# AM13E23219 register map
Vendor: Texas Instruments; File version: 1.0
CPU: CM33 r0p1, little endian, MPU, FPU, VTOR, 4 interrupt priority bits
Registers are 32-bit, read-write, reset 0x0 unless marked. A register's access mark holds for its fields unless they carry their own. Offsets are from the block's base; [hi:lo] are bit positions; lines under a group give offsets from that group; {n}, {i} and the like mark numbered series; 'fields as' and 'values as' point back to an identical list; <NAME> marks a mode.

## UC0_I2CT — UNICOMMI2CT module
Base 0x40610000
Same registers: UC1_I2CT 0x40611000, UC2_I2CT 0x40612000, UC3_I2CT 0x40650000, UC4_I2CT 0x40651000, UC5_I2CT 0x40652000
0x00 CLKDIV — Clock Divider
  [2:0] RATIO — Selects divide ratio of module clock Division factor 0 : DIV_BY_1 1 : DIV_BY_2 .... 63: DIV_BY_64
    0=DIV_BY_1 (Do not divide clock source); {v}=DIV_BY_{v+1} (Divide clock source by {v+1}) (v=1..7); {v}=DIV_BY_{v+1} (Divide clock source by 8) (v=60..63)
0x08 CLKSEL — Clock Select for Ultra Low Power peripherals
  [3] BUSCLK_SEL — Selects BUS CLK as clock source if enabled
    0=DISABLE (Does not select this clock as a source); 1=ENABLE (Select this clock as a source)
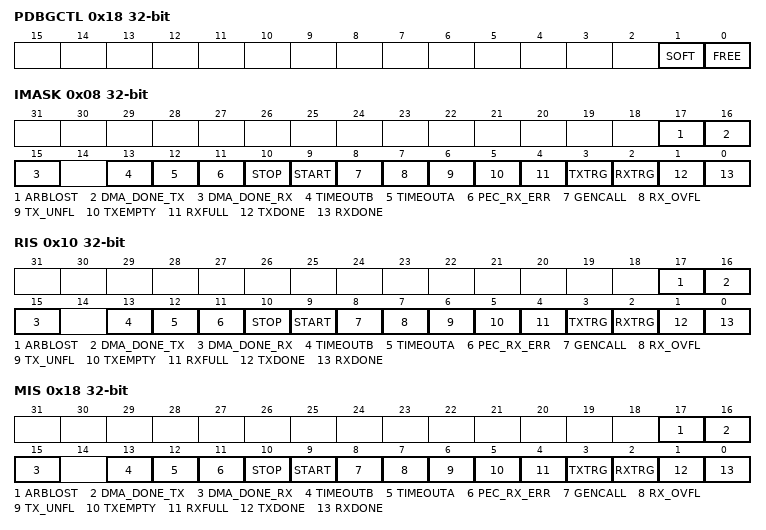
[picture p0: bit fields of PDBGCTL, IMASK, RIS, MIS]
0x18 PDBGCTL — Peripheral Debug Control
  [1] SOFT — Soft halt boundary control. This function is only available, if [FREE] is set to 'STOP'
    0=DEPRECATED (Not supported); 1=DELAYED (The peripheral blocks the debug freeze until it has reached a boundary where it can resume without corruption)
  [0] FREE — Free run control
    0=STOP (The peripheral freezes functionality while the Core Halted input is asserted and resumes when it is deasserted.); 1=RUN (The peripheral ignores the state of the Core Halted input)
0x20 CPU_INT group
  0x00 IIDX ro — Interrupt index
    [7:0] STAT — I2C Module Interrupt Vector Value. This register provides the highes priority interrupt index. A read clears the corresponding interrupt flag in RIS and MISC. 15h-1Fh = Reserved
      0=NO_INTR (No interrupt pending); 1=RXDONEFG (Receive Done Flag); 2=TXDONEFG (Transmit Done Flag); 3=RXTRG (receive FIFO Trigger Level); 4=TXTRG (transmit FIFO Trigger level); 5=RXFULL (RX FIFO FULL Event/interrupt pending); 6=TXEMPTY (Transmit FIFO/Buffer Empty Event/interrupt pending); 7=TX_UNFL (Target TX FIFO underflow); 8=RX_OVFL (Target RX FIFO overflow event); 9=GENCALL (General Call Event); 10=STARTFG (Start Event); 11=STOPFG (Stop Event); 12=PEC_RX_ERR (PEC receive error event); 13=TIMEOUTA (Timeout A Event); 14=TIMEOUTB (Timeout B Event); 16=DMA_DONE_RX (DMA DONE on Channel RX); 17=DMA_DONE_TX (DMA DONE on Channel TX); 18=ARBLOSTFG (Arbitration Lost); 19=DMA_PREIRQ_RX (DMA PRE IRQ INTERRUPT); 20=DMA_PREIRQ_TX (DMA PRE IRQ INTERRUPT)
  0x08 IMASK — Interrupt mask
    [all] fields
      0=CLR (Clear Interrupt Mask); 1=SET (Set Interrupt Mask)
    [17] ARBLOST — Arbitration Lost Interrupt
    [16] DMA_DONE_TX — DMA done for channel 2
    [15] DMA_DONE_RX — DMA done for channel 3
    [13] TIMEOUTB — Timeout B Interrupt
    [12] TIMEOUTA — Timeout A Interrupt
    [11] PEC_RX_ERR — RX Pec Error Interrupt
    [10] STOP
    [9] START
    [8] GENCALL — General Call Interrupt
    [7] RX_OVFL — Target RX FIFO overflow
    [6] TX_UNFL — Target TX FIFO underflow
    [5] TXEMPTY — Target Transmit FIFO Empty interrupt mask
    [4] RXFULL — RXFIFO full event
    [3] TXTRG — Transmit FIFO Trigger
    [2] RXTRG — Receive FIFO Trigger
    [1] TXDONE — Transmit Transaction completed Interrupt
    [0] RXDONE — Receive Data Interrupt Signals that a byte has been received
  0x10 RIS — Raw interrupt status
    [17] ARBLOST — Arbitration Lost Interrupt
      0=CLR (Interrupt did not occur); 1=SET (Set Interrupt Mask)
    [16] DMA_DONE_TX — DMA Done on Event Channel TX
      0=CLR (Clear interrupt); 1=SET (Set interrupt)
    [15] DMA_DONE_RX — DMA Done on Event Channel RX
      0=CLR (Clear interrupt); 1=SET (Set interrupt)
    [13] TIMEOUTB — Timeout B Interrupt
      0=CLR (Interrupt did not occur); 1=SET (Interrupt occured)
    [12] TIMEOUTA — Timeout A Interrupt
      0=CLR (Interrupt did not occur); 1=SET (Set Interrupt Mask)
    [11] PEC_RX_ERR — RX Pec Error Interrupt
      0=CLR (Interrupt did not occur); 1=SET (Interrupt ocuured)
    [10] STOP — Stop Condition Interrupt: set on a STOP condition if this target was being addressed
      0=CLR (Clear Interrupt); 1=SET (Interrupt is set when target is addressed and STOP condition is received)
    [9] START — Start Condition Interrupt: is set after a START condition is received and this target is addressed
      0=CLR (Clear interrupt); 1=SET (Set when a START condition is receivied and address matches target's address)
    [8] GENCALL — General Call Interrupt: set when a general call is received
      0=CLR (Clear Interrupt Mask); 1=SET (Set Interrupt Mask)
    [7] RX_OVFL — Receive FIFO overflow
      0=CLR (Interrupt did not occur); 1=SET (Interrupt Occured)
    [6] TX_UNFL — Transmit FIFO underflow
      0=CLR (Interrupt did not occur); 1=SET (Interrupt occured)
    [5] TXEMPTY — Transmit FIFO Empty interrupt mask
      0=CLR (Interrupt did not occur); 1=SET (Interrupt occured)
    [4] RXFULL — RXFIFO full event
      0=CLR (Clear Interrupt Mask); 1=SET (Interrupt occured)
    [3] TXTRG — Transmit FIFO Trigger
      0=CLR (Clear Interrupt Mask); 1=SET (Set Interrupt Mask)
    [2] RXTRG — Receive FIFO Trigger
      0=CLR (Clear Interrupt Mask); 1=SET (Set Interrupt Mask)
    [1] TXDONE — Transmission Done Interrupt: Set after a byte is transmitted
      0=CLR (Interrupt did not occur); 1=SET (Set Interrupt Mask)
    [0] RXDONE — Receive Done Interrupt: Set after a byte is received
      0=CLR (Interrupt did not occur); 1=SET (Set Interrupt Mask)
  0x18 MIS — Masked interrupt status
    [17] ARBLOST — Arbitration Lost Interrupt
      0=CLR (Interrupt did not occur); 1=SET (Set Interrupt Mask)
    [16] DMA_DONE_TX — DMA Done on Event Channel TX
      0=CLR (Clear MIS); 1=SET (Set MIS)
    [15] DMA_DONE_RX — DMA Done on Event Channel RX
      0=CLR (Clear MIS); 1=SET (Set MIS)
    [13] TIMEOUTB — Timeout B Interrupt
      0=CLR (Clear interrupt mask); 1=SET (Set interrupt mask)
    [12] TIMEOUTA — Timeout A Interrupt
      0=CLR (Interrupt did not occur); 1=SET (Set Interrupt Mask)
    [11] PEC_RX_ERR — Target RX Pec Error Interrupt
      0=CLR (Clear interrupt mask); 1=SET (Set interrupt mask)
    [10] STOP — STOP Detection Interrupt
      0=CLR (Clear MIS); 1=SET (Set MIS)
    [9] START — START Detection Interrupt
      0=CLR (Clear MIS); 1=SET (Set MIS)
    [8] GENCALL — General Call Interrupt
      0=CLR (Interrupt did not occur); 1=SET (Set Interrupt Mask)
    [7] RX_OVFL — Target RX FIFO overflow
      0=CLR (Clear interrupt mask); 1=SET (Set interrupt mask)
    [6] TX_UNFL — Target TX FIFO underflow
      0=CLR (Clear interrupt mask); 1=SET (Set interrupt mask)
    [5] TXEMPTY — Transmit FIFO Empty interrupt mask
      0=CLR (Interrupt did not occur); 1=SET (Interrupt occured)
    [4] RXFULL — RXFIFO full event
      0=CLR (Clear Interrupt Mask); 1=SET (Interrupt occured)
    [3] TXTRG — Transmit FIFO Trigger
      0=CLR (Clear Interrupt Mask); 1=SET (Set Interrupt Mask)
    [2] RXTRG — Receive FIFO Trigger
      0=CLR (Clear Interrupt Mask); 1=SET (Set Interrupt Mask)
    [1] TXDONE — Transmit Transaction completed Interrupt
      0=CLR (Interrupt did not occur); 1=SET (Set Interrupt Mask)
    [0] RXDONE — Receive Data Interrupt Signals that a byte has been received
      0=CLR (Interrupt did not occur); 1=SET (Set Interrupt Mask)
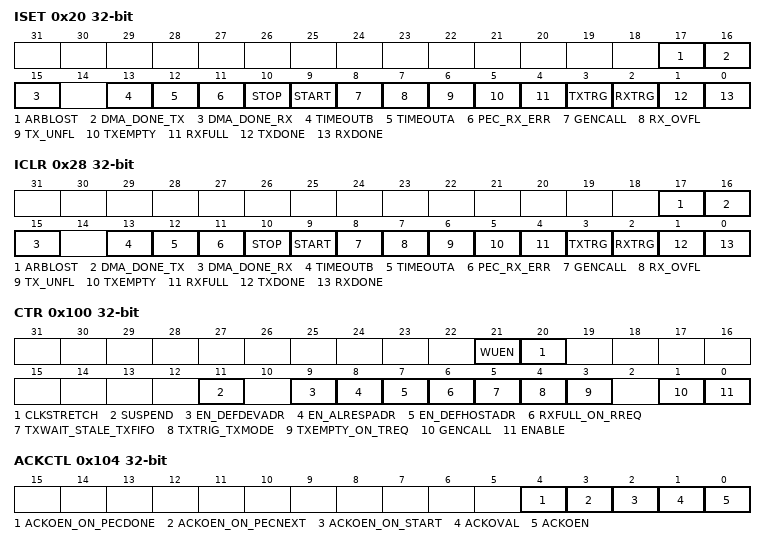
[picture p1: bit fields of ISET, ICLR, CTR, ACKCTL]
  0x20 ISET — Interrupt set
    [17] ARBLOST — Arbitration Lost Interrupt
      0=NO_EFFECT (Writing 0 has no effect); 1=SET (Set Interrupt Mask)
    [16] DMA_DONE_TX — DMA Done on Event Channel TX
      0=NO_EFFECT (Writing 0 has no effect); 1=SET (Set interrupt)
    [15] DMA_DONE_RX — DMA Done on Event Channel RX
      0=NO_EFFECT (Writing 0 has no effect); 1=SET (Set interrupt)
    [13] TIMEOUTB — Timeout B Interrupt
      0=NO_EFFECT (Writing 0 has no effect); 1=SET (Set interrupt)
    [12] TIMEOUTA — Timeout A interrupt
      values as ARBLOST
    [11] PEC_RX_ERR — Target RX Pec Error Interrupt
      0=NO_EFFECT (Writing 0 has no effect); 1=SET (Set interrupt)
    [10] STOP — Stop Condition Interrupt
      0=NO_EFFECT (Writing 0 has no effect); 1=SET (Set interrupt)
    [9] START — Start Condition Interrupt
      0=NO_EFFECT (Writing 0 has no effect); 1=SET (Set interrupt)
    [8] GENCALL — General Call Interrupt
      values as ARBLOST
    [7] RX_OVFL — Target RX FIFO overflow
      0=NO_EFFECT (Writing 0 has no effect); 1=SET (Set interrupt)
    [6] TX_UNFL — Target TX FIFO underflow
      0=NO_EFFECT (Writing 0 has no effect); 1=SET (Set interrupt)
    [5] TXEMPTY — Transmit FIFO Empty interrupt mask
      0=NO_EFFECT (Writing 0 has no effect); 1=SET (Set Interrupt)
    [4] RXFULL — RXFIFO full event
      0=NO_EFFECT (Clear Interrupt Mask); 1=SET (Set Interrupt)
    [3] TXTRG — Target Transmit FIFO Trigger
      0=NO_EFFECT (Clear Interrupt Mask); 1=SET (Set Interrupt Mask)
    [2] RXTRG — Target Receive FIFO Trigger
      values as TXTRG
    [1] TXDONE — Target Transmit Transaction completed Interrupt
      values as ARBLOST
    [0] RXDONE — Target Receive Data Interrupt Signals that a byte has been received
      values as ARBLOST
  0x28 ICLR — Interrupt clear
    [17] ARBLOST — Arbitration Lost Interrupt
      0=NO_EFFECT (Writing 0 has no effect); 1=CLR (Set Interrupt Mask)
    [16] DMA_DONE_TX — DMA Done on Event Channel TX
      0=NO_EFFECT (Writing 0 has no effect); 1=CLR (Clear interrupt)
    [15] DMA_DONE_RX — DMA Done on Event Channel RX
      values as DMA_DONE_TX
    [13] TIMEOUTB — Timeout B Interrupt
      0=NO_EFFECT (Writing 0 has no effect); 1=CLR (Clear Interrupt)
    [12] TIMEOUTA — Timeout A interrupt
      values as ARBLOST
    [11] PEC_RX_ERR — Target RX Pec Error Interrupt
      values as TIMEOUTB
    [10] STOP — Target STOP Detection Interrupt
      values as DMA_DONE_TX
    [9] START — Target START Detection Interrupt
      values as DMA_DONE_TX
    [8] GENCALL — General Call Interrupt
      values as ARBLOST
    [7] RX_OVFL — Target RX FIFO overflow
      values as TIMEOUTB
    [6] TX_UNFL — Target TX FIFO underflow
      values as TIMEOUTB
    [5] TXEMPTY — Transmit FIFO Empty interrupt mask
      values as TIMEOUTB
    [4] RXFULL — RXFIFO full event
      0=NO_EFFECT (Clear Interrupt Mask); 1=CLR (Clear Interrupt)
    [3] TXTRG — Target Transmit FIFO Trigger
      0=NO_EFFECT (Clear Interrupt Mask); 1=CLR (Set Interrupt Mask)
    [2] RXTRG — Target Receive FIFO Trigger
      values as TXTRG
    [1] TXDONE — Target Transmit Transaction completed Interrupt
      values as ARBLOST
    [0] RXDONE — Target Receive Data Interrupt Signals that a byte has been received
      values as ARBLOST
0x50 DMA_TRIG1 group
  0x08 IMASK — Interrupt mask
    [2] RXTRG — Target Receive FIFO Trigger
      0=CLR (Clear Interrupt Mask); 1=SET (Set Interrupt Mask)
  0x10 RIS — Raw interrupt status
    fields as DMA_TRIG1.IMASK
  0x18 MIS — Masked interrupt status
    fields as DMA_TRIG1.IMASK
  0x20 ISET — Interrupt set
    [2] RXTRG — Target Receive FIFO Trigger
      values as CPU_INT.ISET.TXTRG
0x80 DMA_TRIG0 group
  0x08 IMASK — Interrupt mask
    [3] TXTRG — Target Transmit FIFO Trigger
      0=CLR (Clear Interrupt Mask); 1=SET (Set Interrupt Mask)
  0x10 RIS — Raw interrupt status
    fields as DMA_TRIG0.IMASK
  0x18 MIS — Masked interrupt status
    fields as DMA_TRIG0.IMASK
  0x20 ISET — Interrupt set
    [3] TXTRG — Target Transmit FIFO Trigger
      values as CPU_INT.ISET.TXTRG
0xE4 INTCTL — Interrupt control register
  [0] INTEVAL — Writing a 1 to this field re-evaluates the interrupt sources.
    0=DISABLE (The interrupt or event line is disabled.); 1=EVAL (The interrupt or event line is in software mode. Software must clear the RIS.)
0x100 CTR — I2C Target Control Register
  [21] WUEN — Target Wakeup Enable
    0=DISABLE (When 0, the Target is not allowed to clock stretch on START detection); 1=ENABLE (When 1, the Target is allowed to clock stretch on START detection and wait for faster clock to be abvailable. This allows clean wake up support for I2C in low power mode use cases)
  [20] CLKSTRETCH — Clock Stretch Enable
    0=DISABLE (clock stretching is disabled); 1=ENABLE (clock stretching is enabled)
  [11] SUSPEND — Suspend external communication
    0=DISABLE (Functional mode resumed); 1=ENABLE (External communication suspended)
  [9] EN_DEFDEVADR — Enable Default device address
    0=DISABLE (When this bit is 0, the default device address is not matched. NOTE: it may still be matched if programmed inside SOAR/SOAR2.); 1=ENABLE (When this bit is 1, default device address of 7h110_0001 is always matched by the Target address match logic.)
  [8] EN_ALRESPADR — Enable Alert Response Address
    0=DISABLE (When this bit is 0, the alert response address is not matched. NOTE: it may still be matched if programmed inside SOAR/SOAR2); 1=ENABLE (When this bit is 1, alert response address of 7h000_1100 is always matched by the Target address match logic.)
  [7] EN_DEFHOSTADR — Enable Default Host Address
    0=DISABLE (When this bit is 0, the default host address is not matched NOTE: it may still be matched if programmed inside SOAR/SOAR2); 1=ENABLE (When this bit is 1, default host address of 7h000_1000 is always matched by the Target address match logic.)
  [6] RXFULL_ON_RREQ — Rx full interrupt generated on RREQ condition as indicated in SSR
    0=DISABLE (When 0, RIS:SRXFULL will be set when only the Target RX FIFO is full. This allows the SRXFULL interrupt to be used to indicate that the I2C bus is being clock stretched and that the FW must either read the RX FIFO or ACK/NACK the current Rx byte.); 1=ENABLE (When 1, RIS:SRXFULL will be set when the Target State Machine is in the RX_WAIT or RX_ACK_WAIT states which occurs when the I2C transaction is clock stretched because the RX FIFO is full or the ACKOEN has been set and the state machine is waiting for FW to ACK/NACK the current byte.)
  [5] TXWAIT_STALE_TXFIFO — Tx transfer waits when stale data in Tx FIFO. This prevents stale bytes left in the TX FIFO from automatically being sent on the next I2C packet. Note: this should be used with TXEMPTY_ON_TREQ set to prevent the Target State Machine from waiting for TX FIFO data without an interrupt notification when the FIFO data is stale.
    0=DISABLE (When 0, the TX FIFO empty signal to the Target State Machine indicates that the TX FIFO is empty.); 1=ENABLE (When 1, the TX FIFO empty signal to the Target State Machine will indicate that the TX FIFO is empty or that the TX FIFO data is stale. The TX FIFO data is determined to be stale when there is data in the TX FIFO when the Target State Machine leaves the TXMODE as defined in the SSR register. This can occur is a Stop or timeout occur when there are bytes left in the TX FIFO.)
  [4] TXTRIG_TXMODE — Tx Trigger when Target FSM is in Tx Mode
    0=DISABLE (No special behavior); 1=ENABLE (When 1, RIS:TXTRG will be set when the Target TX FIFO has reached the trigger level AND the Target State Machine is in the TXMODE as defined in the SSR register. When cleared RIS:TXTRG will be set when the Target TX FIFO is at or above the trigger level. This setting can be used to hold off the TX DMA until a transaction starts. This allows the DMA to be configured when the I2C is idle but have it wait till the transaction starts to load the Target TX FIFO, so it can load from a memory buffer that might be changing over time.)
  [3] TXEMPTY_ON_TREQ — Tx Empty Interrupt on TREQ
    0=DISABLE (When 0, RIS:TXEMPTY will be set when only the Target TX FIFO is empty. This allows the TXEMPTY interrupt to be used to indicate that the I2C bus is being clock stretched and that Target TX data is required.); 1=ENABLE (When 1, RIS:TXEMPTY will be set when the Target State Machine is in the TX_WAIT state which occurs when the TX FIFO is empty AND the I2C transaction is clock stretched waiting for the FIFO to receive data.)
  [1] GENCALL — General call response enable Modify only when UCSWRST = 1. 0b = Do not respond to a general call 1b = Respond to a general call
    0=DISABLE (Do not respond to a general call); 1=ENABLE (Respond to a general call)
  [0] ENABLE — Setting this bit enables the module.
    0=DISABLE (Disables module operation.); 1=ENABLE (Enables module operation.)
0x104 ACKCTL — I2C Target ACK Control
  [4] ACKOEN_ON_PECDONE — When set, this bit will automatically turn on target acknowledge enable field following the ACK/NACK of the received PEC byte. Status bit ACKOEN will reflect a value of '1' when automatic override enable is used.
    0=DISABLE (No special behavior); 1=ENABLE (When set this bit will automatically turn on the Target ACKOEN field following the ACK/NACK of the received PEC byte.)
  [3] ACKOEN_ON_PECNEXT — When set this bit will automatically turn on the Target acknowledge override following a ACK/NACK of the byte received just prior to the PEC byte. However, setting ACKCTL.ACKOEN bit will not automatically be ACKed/NACKed by the State Machine and firmware must perform this function by writing Target.ACKCTL register. Status bit ACKOEN will reflect a value of '1' when automatic override enable is used.
    0=DISABLE (No special behavior); 1=ENABLE (When set this bit will automatically turn on the Target ACKOEN field following the ACK/NACK of the byte received just prior to the PEC byte. Note that when ACKOEN is set the PEC byte will not automatically be ACKed/NACKed by the State Machine and FW must perform this function by writing Target_SACKCTL.)
  [2] ACKOEN_ON_START — When set this bit will automatically enable target override acknowlede following a Start Condition. Status bit ACKOEN will reflect a value of '1' when automatic override enable is used.
    0=DISABLE (No special behavior); 1=ENABLE (When set this bit will automatically turn on the Target ACKOEN field following a Start Condition.)
  [1] ACKOVAL — ACK Override Value Note: Override control is not applicable to Address frame. Bytes following address frame can be acknowledged using ACKOVAL.
    0=DISABLE (An ACK is sent indicating valid data or command.); 1=ENABLE (A NACK is sent indicating invalid data or command.)
  [0] ACKOEN — I2C Target ACK Override Enable Read SR.ACKOEN to check current status of this bit
    0=DISABLE (A response in not provided.); 1=ENABLE (An ACK or NACK is sent according to the value written to the ACKOVAL bit.)
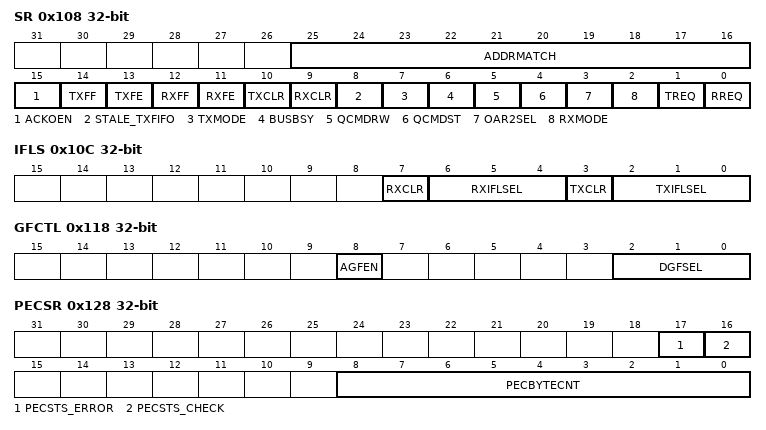
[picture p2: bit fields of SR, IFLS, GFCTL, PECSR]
0x108 SR access per field — Status Register
  [25:16] ADDRMATCH rw — Indicates the address for which Target address match happened
    0=MINIMUM (Minimum Value); 0x3FF=MAXIMUM (Maximum Value)
  [15] ACKOEN ro — Status of ACK Override Enable
    0=DISABLE (ACK override is disabled); 1=ENABLE (ACK override was enabled in design)
  [14] TXFF ro — Transmit FIFO Full The meaning of this bit depends on the state of the FEN bit in the CTL0 register.
    0=CLEARED (The transmitter is not full.); 1=SET (If the FIFO is disabled (FEN is 0), the transmit holding register is full. If the FIFO is enabled (FEN is 1), the transmit FIFO is full.)
  [13] TXFE ro — Transmit FIFO Empty The meaning of this bit depends on the state of the FEN bit in the CTL0 register.
    0=CLEARED (The transmitter has data to transmit.); 1=SET (If the FIFO is disabled (FEN is 0), the transmit holding register is empty. If the FIFO is enabled (FEN is 1), the transmit FIFO is empty.)
  [12] RXFF ro — Receive FIFO Full The meaning of this bit depends on the state of the FEN bit in the CTL0 register.
    0=CLEARED (The receiver can receive data.); 1=SET (If the FIFO is disabled (FEN is 0), the receive holding register is full. If the FIFO is enabled (FEN is 1), the receive FIFO is full.)
  [11] RXFE ro — Receive FIFO Empty The meaning of this bit depends on the state of the FEN bit in the CTL0 register.
    0=CLEARED (The receiver is not empty.); 1=SET (If the FIFO is disabled (FEN is 0), the receive holding register is empty. If the FIFO is enabled (FEN is 1), the receive FIFO is empty.)
  [10] TXCLR ro — TX FIFO Clear Status
    0=CLEARED (FIFO is not cleared); 1=SET (FIFO clear is complete)
  [9] RXCLR ro — RX FIFO Clear Status
    values as TXCLR
  [8] STALE_TXFIFO rw
    0=CLEARED (Tx FIFO is not stale); 1=SET (The TX FIFO is stale. This occurs when the TX FIFO was not emptied during the previous I2C transaction.)
  [7] TXMODE rw — FSM is in TX MODE
    0=CLEARED (State Machine is not in TX_DATA, TX_WAIT, TX_ACK or ADDR_ACK state with the bus direction set to read.); 1=SET (State Machine is in TX_DATA, TX_WAIT, TX_ACK or ADDR_ACK state with the bus direction set to read.)
  [6] BUSBSY rw — I2C bus is busy
    0=CLEARED (The I2C Bus is not busy); 1=SET (The I2C Bus is busy. This is cleared on a timeout.)
  [5] QCMDRW ro — Quick Command Read / Write This bit only has meaning when the QCMDST bit is set. Value Description: 0: Quick command was a write 1: Quick command was a read
    0=CLEARED (Quick command was a write); 1=SET (Quick command was a read)
  [4] QCMDST ro — Quick Command Status Value Description: 0: The last transaction was a normal transaction or a transaction has not occurred. 1: The last transaction was a Quick Command transaction
    0=CLEARED (The last transaction was a normal transaction or a transaction has not occurred.); 1=SET (The last transaction was a Quick Command transaction.)
  [3] OAR2SEL ro — OAR2 Address Matched This bit gets reevaluated after every address comparison.
    0=CLEARED (Either the OAR2 address is not matched or the match is in legacy mode.); 1=SET (OAR2 address matched and ACKed by the Target.)
  [2] RXMODE rw — Target FSM is in Rx MODE
    0=CLEARED (The Target State Machine is not in the RX_DATA, RX_ACK, RX_WAIT, RX_ACK_WAIT or ADDR_ACK state with the bus direction set to write.); 1=SET (The Target State Machine is in the RX_DATA, RX_ACK, RX_WAIT, RX_ACK_WAIT or ADDR_ACK state with the bus direction set to write.)
  [1] TREQ ro — Transmit Request
    0=CLEARED (No outstanding transmit request.); 1=SET (I2C Target is addressed as a transmitter and is using clock stretching to delay the Controller until data has been written to the TXDATA FIFO (TX FIFO is empty).)
  [0] RREQ ro — Receive Request
    0=CLEARED (No outstanding receive data.); 1=SET (Module has outstanding receive data and is using clock stretching to delay the Controller until the data has been read from the RXDATA FIFO (RX FIFO is full).)
0x10C IFLS — Interrupt FIFO Level Select Register
  [7] RXCLR — RX FIFO CLEAR
    0=DISABLE (Disable FIFO clear); 1=ENABLE (Enable FIFO Clear)
  [6:4] RXIFLSEL — FIFO Level Select for generating events (interrupt/dma). Note: for undefined settings the default configuration is used.
    1=LVL_1_4 (RX FIFO >= 1/4 full); 2=LVL_1_2 (RX FIFO >= 1/2 full (default)); 3=LVL_3_4 (RX FIFO >= 3/4 full); 4=LVL_NOT_EMPTY (Opposite of empty); 5=LVL_FULL (RX FIFO is full); 6=LVL_ALMOST_FULL (RX_FIFO >= (MAX_FIFO_LEN -1)); 7=LVL_ALMOST_EMPTY (RX_FIFO <= 1)
  [3] TXCLR — RX FIFO Flush
    0=DISABLE (Disable FIFO clear); 1=ENABLE (Enable FIFO Clear)
  [2:0] TXIFLSEL — FIFO Level Select for generating events (interrupt/dma). Note: for undefined settings the default configuration is used.
    1=LVL_3_4 (TX FIFO <= 3/4 empty); 2=LVL_1_2 (TX FIFO <= 1/2 empty (default)); 3=LVL_1_4 (TX FIFO <= 1/4 empty); 4=LVL_NOT_FULL (Opposite of full); 5=LVL_EMPTY (TX FIFO is empty); 6=LVL_ALMOST_EMPTY (TX FIFO <= 1); 7=LVL_ALMOST_FULL (TX_FIFO >= (MAX_FIFO_LEN -1))
0x118 GFCTL — I2C Glitch Filter Control
  [8] AGFEN — Analog Glitch Suppression Enable
    0=DISABLE (Analog Glitch Filter disable); 1=ENABLE (Analog Glitch Filter enable)
  [2:0] DGFSEL — Glitch Suppression Pulse Width This field controls the pulse width select for glitch suppression on the SCL and SDA lines. The following values are the glitch suppression values in terms of functional clocks. (Core Domain only)
    0=DISABLED (Bypass); 1=CLK_1 (1 clock); 2=CLK_2 (2 clocks); 3=CLK_3 (3 clocks); 4=CLK_4 (4 clocks); 5=CLK_8 (8 clocks); 6=CLK_16 (16 clocks); 7=CLK_31 (31 clocks)
0x120 TTXDATA — I2C TXData
  [7:0] DATA — Transmit Data This byte contains the data to be transferred during the next transaction.
    0=MINIMUM (Smallest value); 255=MAXIMUM (Highest possible value)
0x124 RXDATA ro — I2C RXData
  [7:0] DATA — Received Data. This field contains the last received data.
    values as TTXDATA.DATA
0x128 PECSR — PEC status register
  [17] PECSTS_ERROR — This status bit indicates if a PEC check error occurred in the transaction that occurred before the last Stop. Latched on Stop.
    0=CLEARED (Indicates PEC check error did not occurr in the transaction that occurred before the last Stop); 1=SET (Indicates PEC check error occurred in the transaction that occurred before the last Stop)
  [16] PECSTS_CHECK — This status bit indicates if the PEC was checked in the transaction that occurred before the last Stop. Latched on Stop.
    0=CLEARED (Indicates PEC was not checked in the transaction that occurred before the last Stop); 1=SET (Indicates PEC was checked in the transaction that occurred before the last Stop)
  [8:0] PECBYTECNT — This is the current PEC Byte Count of the State Machine.
    0=MINIMUM (Minimum Value); 0x1FF=MAXIMUM (Maximum Value)
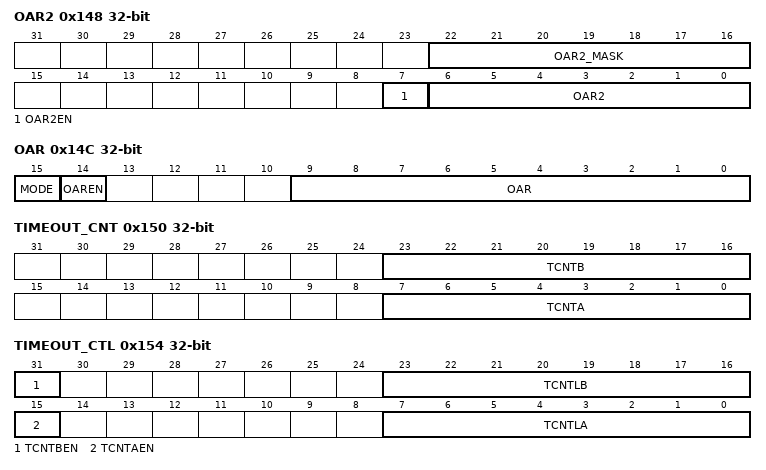
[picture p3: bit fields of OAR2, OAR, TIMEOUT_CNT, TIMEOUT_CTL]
0x148 OAR2 — Own Address 2
  [22:16] OAR2_MASK — Own Address 2 Mask: This field specifies bits A6 through A0 of the Target address. The bits with value 1 in SOAR2.OAR2_MASK field will make the corresponding incoming address bits to match by default regardless of the value inside SOAR2.OAR2 i.e. corresponding SOAR2.OAR2 bit is a dont care.
    0=MINIMUM (Minimum Value); 127=MAXIMUM (Maximum Value)
  [7] OAR2EN — Own Address 2 Enable
    0=DISABLE (The alternate address is disabled.); 1=ENABLE (Enables the use of the alternate address in the OAR2 field.)
  [6:0] OAR2 — Own Address 2This field specifies the alternate OAR2 address.
    0=MINIMUM (Smallest value); 127=MAXIMUM (Highest possible value)
0x14C OAR — I2C Own Address
  [15] MODE — This bit selects the adressing mode to be used. When 0, 7-bit addressing is used. When 1, 10-bit addressing is used.
    0=Enable 7-bit addressing; 1=Enable 10-bit addressing
  [14] OAREN — Own Address Enable
    0=DISABLE (Disable OAR address); 1=ENABLE (Enable OAR address)
  [9:0] OAR — Own Address: This field specifies bits A9 through A0 of the Target address. In 7-bit addressing mode as selected by I2CSOAR.MODE bit, the top 3 bits are don't care
    0=MINIMUM (Smallest value); 0x3FF=MAXIMUM (Highest possible value)
0x150 TIMEOUT_CNT access per field — I2C Timeout Count Register
  [23:16] TCNTB rw — Timeout Count B Current Count: This field contains the upper 8 bits of a 12-bit current counter for timeout counter B
    0=MINIMUM (Smallest Value); 255=MAXIMUM (Highest possible value)
  [7:0] TCNTA ro — Timeout Count A Current Count: This field contains the upper 8 bits of a 12-bit current counter for timeout counter A
    values as TCNTB
0x154 TIMEOUT_CTL — I2C Timeout Count Control Register
  [31] TCNTBEN — Timeout Counter B Enable
    0=DISABLE (Disable Timeout Counter B); 1=ENABLE (Enable Timeout Counter B)
  [23:16] TCNTLB — Timeout Count B Load: Counter B is used for SCL High Detection. This field contains the upper 8 bits of a 12-bit pre-load value for the Timeout B count. NOTE: The value of CNTLB must be greater than 1h. Each count is equal to 1* clock period. For example, with 10MHz functional clock one timeout period will be equal to1*100ns.
    0=MINIMUM (Smallest possible value); 255=MAXIMUM (Highest possible value)
  [15] TCNTAEN — Timeout Counter A Enable
    values as TCNTBEN
  [7:0] TCNTLA — Timeout counter A load value Counter A is used for SCL low detection. This field contains the upper 8 bits of a 12-bit pre-load value for the Timeout A count. NOTE: The value of CNTLA must be greater than 1h. Each count is equal to 520 times the timeout period of functional clock. For example, with 8MHz functional clock and a 100KHz operating I2C clock, one timeout period will be equal to (1 / 8MHz) * 520 or 65 us.
    values as TIMEOUT_CNT.TCNTB
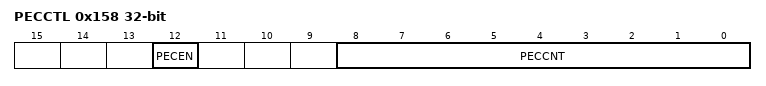
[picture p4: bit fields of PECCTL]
0x158 PECCTL — I2C PEC control register
  [12] PECEN — PEC Enable This bit enables the SMB Packet Error Checking (PEC). When enabled the PEC is calculated on all bits except the Start, Stop, Ack and Nack. The PEC LSFR and the Byte Counter is set to 0 when the State Machine is in the IDLE state, which occur following a Stop or when a timeout occurs. The Counter is also set to 0 after the PEC byte is sent or received. Note that the NACK is automatically send following a PEC byte that results in a PEC error. The PEC Polynomial is x^8 + x^2 + x^1 + 1.
    0=DISABLE (PEC transmission and check is disabled); 1=ENABLE (PEC transmission and check is enabled)
  [8:0] PECCNT — When this field is non zero, the number of I2C data bytes are counted. When the byte count = PECCNT and the state machine is transmitting, the contents of the LSFR is loaded into the shift register instead of the byte received from the Tx FIFO. When the state machine is receiving, after the last bit of this byte is received the LSFR is checked and if it is non-zero, a PEC RX Error interrupt is generated. The I2C packet must be padded to include the PEC byte for both transmit and receive. In transmit mode the FIFO must be loaded with a dummy PEC byte. In receive mode the PEC byte will be passed to the Rx FIFO. In the normal use case, FW would set PECEN=1 and PECCNT=0 and use the ACKOEN until the remaining SMB packet length is known. FW would then set the PECCNT to the remaining packet length (Including PEC bye). FW would then configure DMA to allow the packet to complete unassisted and exit NoAck mode. Note that when the byte count = PEC CNT, the byte count is reset to 0 and multiple PEC calculation can automatically occur within a single I2C transaction
    0=MINIMUM (Minimum Value); 0x1FF=MAXIMUM (Maximum Value)
